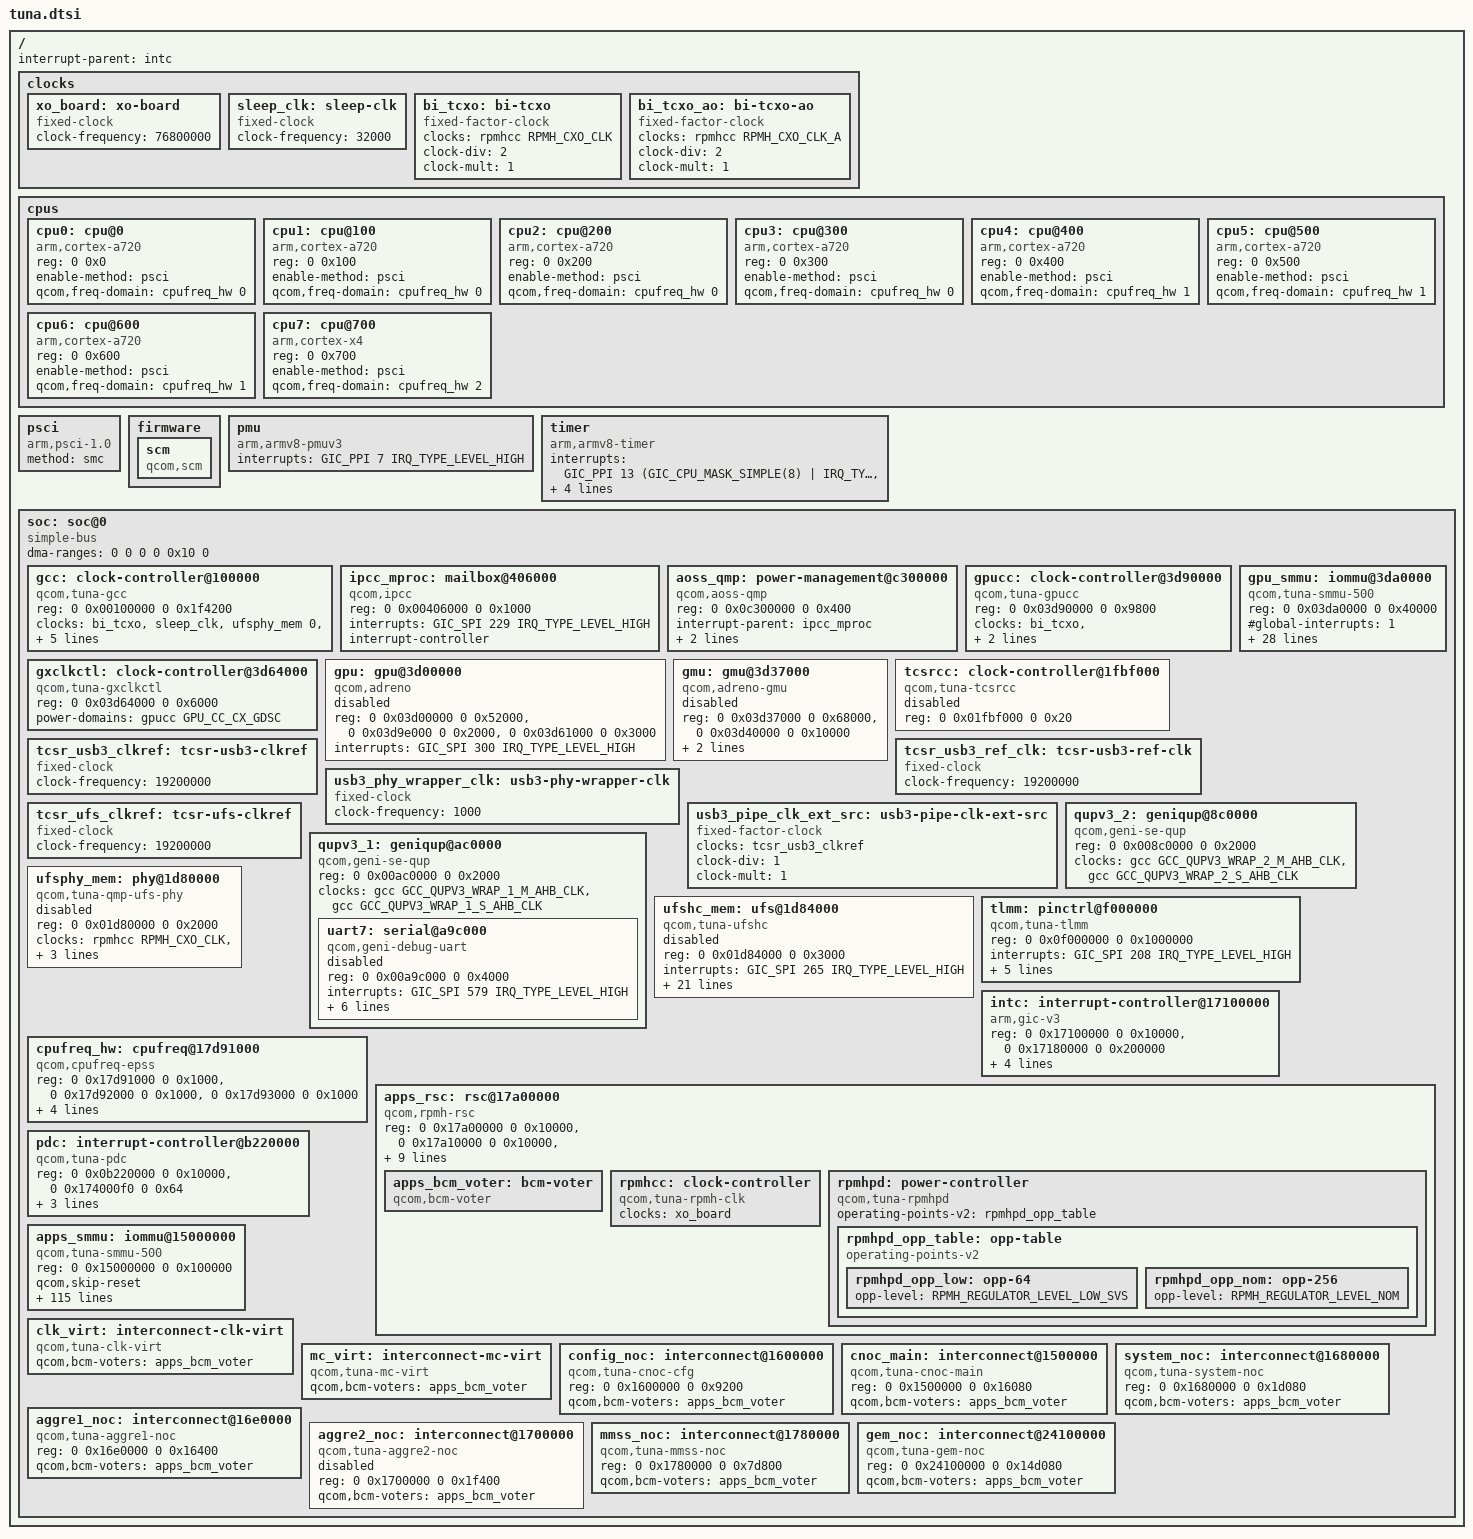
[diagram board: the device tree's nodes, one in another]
// SPDX-License-Identifier: BSD-3-Clause
/* Qualcomm SM8735 (TUNA). Addresses/topology from the captured firmware DT. */
#include <dt-bindings/clock/qcom,gcc-tuna.h>
#include <dt-bindings/clock/qcom,gpucc-tuna.h>
#include <dt-bindings/clock/qcom,dispcc-tuna.h>
#include <dt-bindings/clock/qcom,tcsrcc-sun.h>
#include <dt-bindings/clock/qcom,dsi-phy-28nm.h>
#include <dt-bindings/clock/qcom,rpmh.h>
#include <dt-bindings/gpio/gpio.h>
#include <dt-bindings/interrupt-controller/arm-gic.h>
#include <dt-bindings/interconnect/qcom,tuna.h>
#include <dt-bindings/phy/phy-qcom-qmp.h>
#include <dt-bindings/interconnect/qcom,icc.h>
#include <dt-bindings/power/qcom,rpmhpd.h>
#include <dt-bindings/power/qcom-rpmpd.h>
#include <dt-bindings/soc/qcom,rpmh-rsc.h>

/ {
	#address-cells = <2>;
	#size-cells = <2>;
	interrupt-parent = <&intc>;

	clocks {
		xo_board: xo-board {
			compatible = "fixed-clock";
			clock-frequency = <76800000>;
			#clock-cells = <0>;
		};
		sleep_clk: sleep-clk {
			compatible = "fixed-clock";
			clock-frequency = <32000>;
			#clock-cells = <0>;
		};
		bi_tcxo: bi-tcxo {
			compatible = "fixed-factor-clock";
			clocks = <&rpmhcc RPMH_CXO_CLK>;
			clock-div = <2>;
			clock-mult = <1>;
			#clock-cells = <0>;
		};
		bi_tcxo_ao: bi-tcxo-ao {
			compatible = "fixed-factor-clock";
			clocks = <&rpmhcc RPMH_CXO_CLK_A>;
			clock-div = <2>;
			clock-mult = <1>;
			#clock-cells = <0>;
		};
	};

	cpus {
		#address-cells = <2>;
		#size-cells = <0>;
		cpu0: cpu@0 {
			device_type = "cpu";
			compatible = "arm,cortex-a720";
			reg = <0 0x0>;
			enable-method = "psci";
			#cooling-cells = <2>;
			qcom,freq-domain = <&cpufreq_hw 0>;
		};
		cpu1: cpu@100 {
			device_type = "cpu";
			compatible = "arm,cortex-a720";
			reg = <0 0x100>;
			enable-method = "psci";
			#cooling-cells = <2>;
			qcom,freq-domain = <&cpufreq_hw 0>;
		};
		cpu2: cpu@200 {
			device_type = "cpu";
			compatible = "arm,cortex-a720";
			reg = <0 0x200>;
			enable-method = "psci";
			#cooling-cells = <2>;
			qcom,freq-domain = <&cpufreq_hw 0>;
		};
		cpu3: cpu@300 {
			device_type = "cpu";
			compatible = "arm,cortex-a720";
			reg = <0 0x300>;
			enable-method = "psci";
			#cooling-cells = <2>;
			qcom,freq-domain = <&cpufreq_hw 0>;
		};
		cpu4: cpu@400 {
			device_type = "cpu";
			compatible = "arm,cortex-a720";
			reg = <0 0x400>;
			enable-method = "psci";
			#cooling-cells = <2>;
			qcom,freq-domain = <&cpufreq_hw 1>;
		};
		cpu5: cpu@500 {
			device_type = "cpu";
			compatible = "arm,cortex-a720";
			reg = <0 0x500>;
			enable-method = "psci";
			#cooling-cells = <2>;
			qcom,freq-domain = <&cpufreq_hw 1>;
		};
		cpu6: cpu@600 {
			device_type = "cpu";
			compatible = "arm,cortex-a720";
			reg = <0 0x600>;
			enable-method = "psci";
			#cooling-cells = <2>;
			qcom,freq-domain = <&cpufreq_hw 1>;
		};
		cpu7: cpu@700 {
			device_type = "cpu";
			compatible = "arm,cortex-x4";
			reg = <0 0x700>;
			enable-method = "psci";
			#cooling-cells = <2>;
			qcom,freq-domain = <&cpufreq_hw 2>;
		};
	};

	psci { compatible = "arm,psci-1.0"; method = "smc"; };
	firmware { scm: scm { compatible = "qcom,scm"; }; };
	pmu { compatible = "arm,armv8-pmuv3"; interrupts = <GIC_PPI 7 IRQ_TYPE_LEVEL_HIGH>; };
	timer {
		compatible = "arm,armv8-timer";
		/* Four PPIs and the CPU mask match the captured firmware DT. */
		interrupts = <GIC_PPI 13 (GIC_CPU_MASK_SIMPLE(8) | IRQ_TYPE_LEVEL_LOW)>,
			     <GIC_PPI 14 (GIC_CPU_MASK_SIMPLE(8) | IRQ_TYPE_LEVEL_LOW)>,
			     <GIC_PPI 11 (GIC_CPU_MASK_SIMPLE(8) | IRQ_TYPE_LEVEL_LOW)>,
			     <GIC_PPI 12 (GIC_CPU_MASK_SIMPLE(8) | IRQ_TYPE_LEVEL_LOW)>;
		clock-frequency = <19200000>;
	};

	soc: soc@0 {
		compatible = "simple-bus";
		#address-cells = <2>;
		#size-cells = <2>;
		ranges = <0 0 0 0 0x10 0>;
		dma-ranges = <0 0 0 0 0x10 0>;

		gcc: clock-controller@100000 {
			compatible = "qcom,tuna-gcc";
			reg = <0 0x00100000 0 0x1f4200>;
			clocks = <&bi_tcxo>, <&sleep_clk>,
				 <&ufsphy_mem 0>, <&ufsphy_mem 1>, <&ufsphy_mem 2>,
				 <&usb3_phy_wrapper_clk>;
			clock-names = "bi_tcxo", "sleep_clk", "ufs_phy_rx_symbol_0_clk",
				      "ufs_phy_rx_symbol_1_clk", "ufs_phy_tx_symbol_0_clk",
				      "usb3_phy_wrapper_gcc_usb30_pipe_clk";
			power-domains = <&rpmhpd RPMHPD_CX>, <&rpmhpd RPMHPD_MX>;
			required-opps = <&rpmhpd_opp_nom>, <&rpmhpd_opp_nom>;
			#clock-cells = <1>;
			#reset-cells = <1>;
			#power-domain-cells = <1>;
		};

		/*
		 * The GPU clock controller and the GX clock/power block. Both were
		 * missing from this file while gpucc-tuna.c sat in the tree
		 * unbuilt, which is why the GPU had no way to be clocked no matter
		 * what the board file declared.
		 *
		 * Addresses, window sizes and the clock inputs come from the
		 * board's factory device tree, which names the same blocks
		 * "qcom,tuna-gpucc" and "qcom,tuna-gx_clkctl". The window is
		 * 0x9800 because gpucc-tuna.c's regmap has max_register 0x964c;
		 * a smaller window would truncate it.
		 *
		 * The two GPLL0 inputs are the ones gcc-tuna.c registers. The
		 * driver used to ask for "gpll0_out_main"/"gpll0_out_main_div",
		 * which nothing on this platform provides -- see the note in
		 * gpucc-tuna.c.
		 */
		/*
		 * IPCC and the AOSS QMP that rides on it.
		 *
		 * The GPU needs these. a6xx_gmu_acd_probe() sends the GPU's ACD state to
		 * AOSS with qmp_send(), and refuses to continue when the GPU has ACD
		 * levels but qcom,qmp is absent ("Unable to send ACD state to AOSS",
		 * -EINVAL). This part has ACD -- the vendor's gen8_6_0 entry lists
		 * ADRENO_ACD -- and the vendor sends that state as the very first thing
		 * in gen8_gmu_first_boot, before the CX GDSC, before the clocks and
		 * before the firmware is loaded.
		 *
		 * Both nodes come from the SoC's own vendor device tree, including the
		 * IPCC client/signal numbers; the vendor's GMU node carries
		 * qcom,qmp = <&aoss_qmp>, which is the property the driver reads through
		 * qmp_get().
		 */
		ipcc_mproc: mailbox@406000 {
			compatible = "qcom,ipcc";
			reg = <0 0x00406000 0 0x1000>;
			interrupts = <GIC_SPI 229 IRQ_TYPE_LEVEL_HIGH>;
			interrupt-controller;
			#interrupt-cells = <3>;
			#mbox-cells = <2>;
		};

		aoss_qmp: power-management@c300000 {
			compatible = "qcom,aoss-qmp";
			reg = <0 0x0c300000 0 0x400>;
			interrupt-parent = <&ipcc_mproc>;
			interrupts = <0 0 IRQ_TYPE_EDGE_RISING>;
			mboxes = <&ipcc_mproc 0 0>;
			#power-domain-cells = <1>;
			#clock-cells = <0>;
		};

		gpucc: clock-controller@3d90000 {
			compatible = "qcom,tuna-gpucc";
			reg = <0 0x03d90000 0 0x9800>;
			clocks = <&bi_tcxo>,
				 <&gcc GCC_GPU_GPLL0_CPH_CLK_SRC>,
				 <&gcc GCC_GPU_GPLL0_DIV_CPH_CLK_SRC>;
			clock-names = "bi_tcxo", "gcc_gpu_gpll0_cph_clk_src",
				      "gcc_gpu_gpll0_div_cph_clk_src";
			#clock-cells = <1>;
			#reset-cells = <1>;
			#power-domain-cells = <1>;
		};

		/*
		 * The GX rail. Its GDSC is what the GPU core sits on, and it is
		 * parented to gpucc's power domain, so this node has to follow
		 * gpucc rather than be declared before it.
		 */
		gxclkctl: clock-controller@3d64000 {
			compatible = "qcom,tuna-gxclkctl";
			/*
			 * The block starts at 0x3d64000 and the GX GDSC register is
			 * at offset 0x4024 inside it, which is the 0x3d68024 the
			 * factory device tree names. Declaring the base as 0x3d68024
			 * with a size of 8 -- as this node first did -- gives a
			 * regmap whose offsets are counted from the wrong place, so
			 * the driver would have read and written the wrong register
			 * even once it matched.
			 *
			 * kaanapali.dtsi declares the same block the same way
			 * (0x3d64000, size 0x6000), which is what this follows.
			 */
			reg = <0 0x03d64000 0 0x6000>;

			/*
			 * The GX rail's parents. RPMHPD_GFX and RPMHPD_GMXC are the
			 * RPMh corners and gpucc's CX GDSC is the local one, same
			 * three as kaanapali's node. Without these the rail has no
			 * supply to switch, which matters because this is the domain
			 * the GPU core comes up on.
			 */
			/*
			 * One domain, which is what the SoC's own vendor devicetree
			 * says (oneplus-dt .../devicetree/qcom/tuna.dtsi):
			 *
			 *     gxclkctl: clock-controller@3d68024 {
			 *             compatible = "qcom,tuna-gx_clkctl";
			 *             reg = <0x3d68024 0x8>;
			 *             power-domains = <&gpucc GPU_CC_CX_GDSC>;
			 *             vdd_gx-supply = <&VDD_GFX_MXC_VOTER_LEVEL>;
			 *     };
			 *
			 * This node previously carried three domains copied from
			 * kaanapali.dtsi (RPMHPD_GFX, RPMHPD_GMXC and the CX GDSC).
			 * kaanapali is a different SoC and that was the mistake
			 * AGENTS.md section 6.1 warns about: sibling values are a
			 * reading dictionary, not a source. The vdd_gx supply is a
			 * qcom,stub-regulator in the vendor tree, i.e. a bring-up
			 * placeholder rather than a real rail, so voltage is left to
			 * RPMh here for the same reason.
			 */
			power-domains = <&gpucc GPU_CC_CX_GDSC>;

			#power-domain-cells = <1>;
		};

		/*
		 * The GPU's own SMMU. Address, interrupt list and the clock/power
		 * inputs come from the board's factory device tree, which names
		 * the same block "kgsl-smmu@3da0000" with
		 * compatible = "qcom,qsmmu-v500", "qcom,adreno-smmu".
		 *
		 * The compatible list is reordered for mainline, whose binding
		 * wants the SoC-specific string first: sm8650.dtsi, whose
		 * adreno_smmu sits at this very address with the same first ten
		 * global interrupts (GIC_SPI 673, then 677-687), is the template.
		 * Beyond those ten the two parts differ, so the full 25-interrupt
		 * list here is the vendor's, not sm8650's.
		 *
		 * qcom,use-3-lvl-tables is a vendor property and is deliberately
		 * not carried over: mainline's arm-smmu-qcom sets the table format
		 * from the compatible, and passing a vendor-only property would
		 * have no effect while looking like it did.
		 */
		gpu_smmu: iommu@3da0000 {
			compatible = "qcom,tuna-smmu-500", "qcom,adreno-smmu",
				     "qcom,smmu-500", "arm,mmu-500";
			reg = <0 0x03da0000 0 0x40000>;
			#iommu-cells = <2>;
			#global-interrupts = <1>;
			interrupts = <GIC_SPI 673 IRQ_TYPE_LEVEL_HIGH>,
				     <GIC_SPI 677 IRQ_TYPE_LEVEL_HIGH>,
				     <GIC_SPI 678 IRQ_TYPE_LEVEL_HIGH>,
				     <GIC_SPI 679 IRQ_TYPE_LEVEL_HIGH>,
				     <GIC_SPI 680 IRQ_TYPE_LEVEL_HIGH>,
				     <GIC_SPI 681 IRQ_TYPE_LEVEL_HIGH>,
				     <GIC_SPI 682 IRQ_TYPE_LEVEL_HIGH>,
				     <GIC_SPI 683 IRQ_TYPE_LEVEL_HIGH>,
				     <GIC_SPI 684 IRQ_TYPE_LEVEL_HIGH>,
				     <GIC_SPI 685 IRQ_TYPE_LEVEL_HIGH>,
				     <GIC_SPI 686 IRQ_TYPE_LEVEL_HIGH>,
				     <GIC_SPI 687 IRQ_TYPE_LEVEL_HIGH>,
				     <GIC_SPI 422 IRQ_TYPE_LEVEL_HIGH>,
				     <GIC_SPI 476 IRQ_TYPE_LEVEL_HIGH>,
				     <GIC_SPI 574 IRQ_TYPE_LEVEL_HIGH>,
				     <GIC_SPI 575 IRQ_TYPE_LEVEL_HIGH>,
				     <GIC_SPI 576 IRQ_TYPE_LEVEL_HIGH>,
				     <GIC_SPI 577 IRQ_TYPE_LEVEL_HIGH>,
				     <GIC_SPI 659 IRQ_TYPE_LEVEL_HIGH>,
				     <GIC_SPI 661 IRQ_TYPE_LEVEL_HIGH>,
				     <GIC_SPI 664 IRQ_TYPE_LEVEL_HIGH>,
				     <GIC_SPI 665 IRQ_TYPE_LEVEL_HIGH>,
				     <GIC_SPI 666 IRQ_TYPE_LEVEL_HIGH>,
				     <GIC_SPI 668 IRQ_TYPE_LEVEL_HIGH>,
				     <GIC_SPI 699 IRQ_TYPE_LEVEL_HIGH>;
			clocks = <&gpucc GPU_CC_HLOS1_VOTE_GPU_SMMU_CLK>;
			clock-names = "gpu_cc_hlos1_vote_gpu_smmu";
			power-domains = <&gpucc 1>;
			dma-coherent;
		};

		/*
		 * The GPU and its GMU. Both addresses, the interrupt numbers and the
		 * register windows come from the board's factory device tree, which
		 * names them "kgsl-3d0@3d00000" and "qcom,gmu@3d37000".
		 *
		 * They are siblings, not parent and child: mainline reaches the GMU
		 * through the GPU node's qcom,gmu phandle, which the board file sets,
		 * and both therefore have to be real platform devices.
		 *
		 * The GPU status stays disabled here and is enabled per board, since
		 * which chip id the node advertises is a property of the part fitted.
		 */
		gpu: gpu@3d00000 {
			compatible = "qcom,adreno";
			reg = <0 0x03d00000 0 0x52000>,
			      <0 0x03d9e000 0 0x2000>,
			      <0 0x03d61000 0 0x3000>;
			reg-names = "kgsl_3d0_reg_memory", "cx_mem", "cx_dbgc";
			interrupts = <GIC_SPI 300 IRQ_TYPE_LEVEL_HIGH>;
			interrupt-names = "kgsl_3d0_irq";
			status = "disabled";
		};

		gmu: gmu@3d37000 {
			compatible = "qcom,adreno-gmu";
			reg = <0 0x03d37000 0 0x68000>,
			      <0 0x03d40000 0 0x10000>;
			reg-names = "gmu", "gmu_ao_blk_dec0";
			interrupts = <GIC_SPI 304 IRQ_TYPE_LEVEL_HIGH>,
				     <GIC_SPI 305 IRQ_TYPE_LEVEL_HIGH>;
			interrupt-names = "hfi", "gmu";
			status = "disabled";
		};

		tcsrcc: clock-controller@1fbf000 {
			compatible = "qcom,tuna-tcsrcc";
			reg = <0 0x01fbf000 0 0x20>;
			#clock-cells = <1>;
			/*
			 * The TCSR block is closed to the non-secure kernel -- merely probing its
			 * clock driver stalls the AXI bus -- so the reference gates the bootloader
			 * already opened are modelled as fixed clocks. Enabling it instead leaves
			 * the provider absent, the eUSB2 PHY's devm_clk_get() deferred forever and
			 * the board without USB.
			 */
			status = "disabled";
		};

		/*
		 * The PHY's reference is ref_clk_src, taken from the TCSR syscon and
		 * routed through the pipe_clk_ext_src mux that the vendor driver switches
		 * between bring-up and teardown. TCSR is closed to the non-secure kernel,
		 * so both are fixed clocks. mainline has no generic DT clock mux, so the
		 * mux is a fixed-factor clock sourced from ref_clk_src -- the parent the
		 * vendor driver selects.
		 */
		tcsr_usb3_clkref: tcsr-usb3-clkref {
			compatible = "fixed-clock";
			#clock-cells = <0>;
			clock-frequency = <19200000>;
		};

		tcsr_usb3_ref_clk: tcsr-usb3-ref-clk {
			compatible = "fixed-clock";
			#clock-cells = <0>;
			clock-frequency = <19200000>;
		};

		/*
		 * gcc-tuna.c looks this mux's parents up by fw_name, and GCC probes long
		 * before the QMP PHY: pointing the entry at the PHY leaves parent 0 NULL,
		 * the mux selects nothing and the PIPE chain reports rate 0 with
		 * clk_round_rate() = -EINVAL. With no PIPE clock the link never trains
		 * above High Speed, where the vendor's comes up at SuperSpeed. 1000 Hz is
		 * the placeholder rate the vendor's clock tree reports.
		 */
		usb3_phy_wrapper_clk: usb3-phy-wrapper-clk {
			compatible = "fixed-clock";
			#clock-cells = <0>;
			clock-frequency = <1000>;
		};

		usb3_pipe_clk_ext_src: usb3-pipe-clk-ext-src {
			compatible = "fixed-factor-clock";
			clocks = <&tcsr_usb3_clkref>;
			clock-div = <1>;
			clock-mult = <1>;
			#clock-cells = <0>;
		};

		tcsr_ufs_clkref: tcsr-ufs-clkref {
			compatible = "fixed-clock";
			#clock-cells = <0>;
			clock-frequency = <19200000>;
		};

		/*
		 * The second GENI QUP wrapper. WRAP 2 is where this board's I2C
		 * devices actually are -- see meizu-m2582-i2c.dtsi -- and it was
		 * missing from this file entirely, so its children could not be
		 * declared at all.
		 *
		 * The window, the two AHB clocks and the SE clock indices are each
		 * confirmed twice: by the board's vendor device tree overlay
		 * (qupv3_2 at 0x8c0000, clocks <&gcc 0x6d>, <&gcc 0x6e>, and
		 * <&gcc 0x59..0x5f> for its serial engines) and by qcom,gcc-tuna.h,
		 * where those indices are exactly GCC_QUPV3_WRAP_2_M_AHB_CLK,
		 * GCC_QUPV3_WRAP_2_S_AHB_CLK and GCC_QUPV3_WRAP2_S0..S7_CLK.
		 *
		 * Its serial engines live in meizu-m2582-i2c.dtsi rather than here,
		 * because which of them this board wires up is a board fact.
		 */
		qupv3_2: geniqup@8c0000 {
			compatible = "qcom,geni-se-qup";
			reg = <0 0x008c0000 0 0x2000>;
			clocks = <&gcc GCC_QUPV3_WRAP_2_M_AHB_CLK>, <&gcc GCC_QUPV3_WRAP_2_S_AHB_CLK>;
			clock-names = "m-ahb", "s-ahb";
			#address-cells = <2>;
			#size-cells = <2>;
			ranges;
		};

		qupv3_1: geniqup@ac0000 {
			compatible = "qcom,geni-se-qup";
			reg = <0 0x00ac0000 0 0x2000>;
			clocks = <&gcc GCC_QUPV3_WRAP_1_M_AHB_CLK>, <&gcc GCC_QUPV3_WRAP_1_S_AHB_CLK>;
			clock-names = "m-ahb", "s-ahb";
			#address-cells = <2>;
			#size-cells = <2>;
			ranges;

			uart7: serial@a9c000 {
				compatible = "qcom,geni-debug-uart";
				reg = <0 0x00a9c000 0 0x4000>;
				interrupts = <GIC_SPI 579 IRQ_TYPE_LEVEL_HIGH>;
				clocks = <&gcc GCC_QUPV3_WRAP1_S7_CLK>;
				clock-names = "se";
				interconnects = <&clk_virt MASTER_QUP_CORE_1 QCOM_ICC_TAG_ALWAYS &clk_virt SLAVE_QUP_CORE_1 QCOM_ICC_TAG_ALWAYS>,
						<&gem_noc MASTER_APPSS_PROC QCOM_ICC_TAG_ALWAYS &config_noc SLAVE_QUP_1 QCOM_ICC_TAG_ALWAYS>;
				interconnect-names = "qup-core", "qup-config";
				status = "disabled";
			};
		};

		ufsphy_mem: phy@1d80000 {
			compatible = "qcom,tuna-qmp-ufs-phy";
			reg = <0 0x01d80000 0 0x2000>;
			clocks = <&rpmhcc RPMH_CXO_CLK>, <&gcc GCC_UFS_PHY_PHY_AUX_CLK>, <&tcsr_ufs_clkref>;
			clock-names = "ref", "ref_aux", "qref";
			resets = <&ufshc_mem 0>;
			reset-names = "ufsphy";
			power-domains = <&gcc GCC_UFS_MEM_PHY_GDSC>;
			#clock-cells = <1>;
			#phy-cells = <0>;
			status = "disabled";
		};

		ufshc_mem: ufs@1d84000 {
			compatible = "qcom,tuna-ufshc", "qcom,ufshc", "jedec,ufs-2.0";
			reg = <0 0x01d84000 0 0x3000>;
			interrupts = <GIC_SPI 265 IRQ_TYPE_LEVEL_HIGH>;
			clocks = <&gcc GCC_UFS_PHY_AXI_CLK>, <&gcc GCC_AGGRE_UFS_PHY_AXI_CLK>,
				 <&gcc GCC_UFS_PHY_AHB_CLK>, <&gcc GCC_UFS_PHY_UNIPRO_CORE_CLK>,
				 <&rpmhcc RPMH_LN_BB_CLK3>, <&gcc GCC_UFS_PHY_TX_SYMBOL_0_CLK>,
				 <&gcc GCC_UFS_PHY_RX_SYMBOL_0_CLK>, <&gcc GCC_UFS_PHY_RX_SYMBOL_1_CLK>;
			clock-names = "core_clk", "bus_aggr_clk", "iface_clk", "core_clk_unipro",
				      "ref_clk", "tx_lane0_sync_clk", "rx_lane0_sync_clk", "rx_lane1_sync_clk";
			/*
			 * A non-zero min/max range makes the UFS core register a devfreq device,
			 * and ufs_devfreq_scale() then walks of_parse_clkspec() every 60 ms -- a
			 * path that oopses on this board in __pi_strcmp about two seconds into
			 * boot. Collapsing each range to one value keeps the property present
			 * while making scaling impossible. Pin to the top of the range: at 100 MHz
			 * the link does not work at all.
			 */
			freq-table-hz = <403000000 403000000>, <0 0>, <0 0>, <403000000 403000000>,
					<0 0>, <0 0>, <0 0>, <0 0>;
			interconnects = <&aggre1_noc MASTER_UFS_MEM QCOM_ICC_TAG_ALWAYS &mc_virt SLAVE_EBI1 QCOM_ICC_TAG_ALWAYS>,
					<&gem_noc MASTER_APPSS_PROC QCOM_ICC_TAG_ALWAYS &config_noc SLAVE_UFS_MEM_CFG QCOM_ICC_TAG_ALWAYS>;
			interconnect-names = "ufs-ddr", "cpu-ufs";
			power-domains = <&gcc GCC_UFS_PHY_GDSC>;
			dma-coherent;
			lanes-per-direction = <2>;
			phys = <&ufsphy_mem>;
			phy-names = "ufsphy";
			resets = <&gcc GCC_UFS_PHY_BCR>;
			reset-names = "rst";
			reset-gpios = <&tlmm 191 GPIO_ACTIVE_LOW>;
			#reset-cells = <1>;
			status = "disabled";
		};

		tlmm: pinctrl@f000000 {
			compatible = "qcom,tuna-tlmm";
			reg = <0 0x0f000000 0 0x1000000>;
			interrupts = <GIC_SPI 208 IRQ_TYPE_LEVEL_HIGH>;
			gpio-controller;
			#gpio-cells = <2>;
			interrupt-controller;
			#interrupt-cells = <2>;
			#address-cells = <0>;
			gpio-ranges = <&tlmm 0 0 192>;
			gpio-reserved-ranges = <4 4>, <54 1>, <82 2>;
			wakeup-parent = <&pdc>;
		};

		intc: interrupt-controller@17100000 {
			compatible = "arm,gic-v3";
			reg = <0 0x17100000 0 0x10000>, <0 0x17180000 0 0x200000>;
			interrupts = <GIC_PPI 9 IRQ_TYPE_LEVEL_HIGH>;
			interrupt-controller;
			#interrupt-cells = <3>;
			#address-cells = <2>;
			#size-cells = <2>;
			ranges;
			#redistributor-regions = <1>;
			redistributor-stride = <0 0x40000>;
		};

		/*
		 * EPSS runs CPU DVFS in hardware. An RPMh vote only lands if it agrees
		 * with what the firmware already programmed, so frequency and voltage
		 * scaling happen here rather than in the OS. Addresses, clocks and
		 * interrupts are from the factory device tree; the layout matches
		 * sm8250's EPSS, only the base differs.
		 */
		cpufreq_hw: cpufreq@17d91000 {
			compatible = "qcom,cpufreq-epss";
			reg = <0 0x17d91000 0 0x1000>,
			      <0 0x17d92000 0 0x1000>,
			      <0 0x17d93000 0 0x1000>;
			reg-names = "freq-domain0", "freq-domain1", "freq-domain2";

			/*
			 * "xo" must be the divided 19.2 MHz clock, not RPMH_CXO_CLK
			 * itself. The driver turns an LUT entry into a frequency as
			 * xo_rate * lval / 1000, so feeding it the undivided 38.4 MHz
			 * doubles every frequency it reports -- which is exactly what
			 * happened: the hardware LUT tops out at 2016/2803/3206 MHz
			 * for the three domains, matching the A720 silver, A720 gold
			 * and X4 parts, but the driver announced 4032/5414/5913 MHz.
			 * bi_tcxo below is the fixed divide-by-2 of RPMH_CXO_CLK;
			 * sm8650 and sm8750 name the same thing bi_tcxo_div2.
			 */
			clocks = <&bi_tcxo>, <&gcc GCC_GPLL0>;
			clock-names = "xo", "alternate";

			interrupts = <GIC_SPI 30 IRQ_TYPE_LEVEL_HIGH>,
				     <GIC_SPI 31 IRQ_TYPE_LEVEL_HIGH>,
				     <GIC_SPI 19 IRQ_TYPE_LEVEL_HIGH>;
			interrupt-names = "dcvsh-irq-0", "dcvsh-irq-1", "dcvsh-irq-2";

			#freq-domain-cells = <1>;
		};

		apps_rsc: rsc@17a00000 {
			compatible = "qcom,rpmh-rsc";
			reg = <0 0x17a00000 0 0x10000>, <0 0x17a10000 0 0x10000>, <0 0x17a20000 0 0x10000>;
			reg-names = "drv-0", "drv-1", "drv-2";
			interrupts = <GIC_SPI 3 IRQ_TYPE_LEVEL_HIGH>, <GIC_SPI 4 IRQ_TYPE_LEVEL_HIGH>, <GIC_SPI 5 IRQ_TYPE_LEVEL_HIGH>;
			qcom,drv-id = <2>;
			qcom,tcs-offset = <0xd00>;
			qcom,tcs-config = <ACTIVE_TCS 3>, <SLEEP_TCS 2>, <WAKE_TCS 2>, <CONTROL_TCS 0>;
			label = "apps_rsc";
			apps_bcm_voter: bcm-voter { compatible = "qcom,bcm-voter"; };
			rpmhcc: clock-controller {
				compatible = "qcom,tuna-rpmh-clk";
				clocks = <&xo_board>;
				clock-names = "xo";
				#clock-cells = <1>;
			};
			rpmhpd: power-controller {
				compatible = "qcom,tuna-rpmhpd";
				#power-domain-cells = <1>;
				operating-points-v2 = <&rpmhpd_opp_table>;
				rpmhpd_opp_table: opp-table {
					compatible = "operating-points-v2";
					rpmhpd_opp_low: opp-64 { opp-level = <RPMH_REGULATOR_LEVEL_LOW_SVS>; };
					rpmhpd_opp_nom: opp-256 { opp-level = <RPMH_REGULATOR_LEVEL_NOM>; };
				};
			};
		};

		pdc: interrupt-controller@b220000 {
			compatible = "qcom,tuna-pdc", "qcom,pdc";
			reg = <0 0x0b220000 0 0x10000>, <0 0x174000f0 0 0x64>;
			#interrupt-cells = <2>;
			#address-cells = <0>;
			interrupt-controller;
			qcom,pdc-ranges = <0 480 8 8 719 1 9 718 1 10 230 1 11 724 1 12 716 1 13 727 1 14 720 1 15 726 1 16 721 1 17 262 1 18 70 1 19 723 1 20 234 1 22 725 1 23 231 1 24 504 14 40 520 6 51 531 4 58 538 2 61 541 4 67 547 27 94 609 31 125 63 1 126 366 2 128 374 1 129 378 1 130 428 1 131 434 2 133 437 1 134 452 2 136 458 2 138 464 11 149 671 1 150 688 1 151 714 2 153 722 1 154 255 1 155 269 2 157 276 1 158 287 1 159 306 4>;
		};

		apps_smmu: iommu@15000000 {
			compatible = "qcom,tuna-smmu-500", "qcom,smmu-500", "arm,mmu-500";
			reg = <0 0x15000000 0 0x100000>;
			/*
			 * Removing this property takes the board down: black screen, no USB
			 * enumeration, no console. The bootloader leaves this SMMU translating
			 * for UFS and USB, and re-initialising every SMR and context bank from
			 * the non-secure kernel breaks them. Verified as an isolated change.
			 */
			qcom,skip-reset;
			#iommu-cells = <2>;
			#global-interrupts = <1>;
			dma-coherent;
			interrupts = <GIC_SPI 65 IRQ_TYPE_LEVEL_HIGH>,
				     <GIC_SPI 97 IRQ_TYPE_LEVEL_HIGH>,
				     <GIC_SPI 98 IRQ_TYPE_LEVEL_HIGH>,
				     <GIC_SPI 99 IRQ_TYPE_LEVEL_HIGH>,
				     <GIC_SPI 100 IRQ_TYPE_LEVEL_HIGH>,
				     <GIC_SPI 101 IRQ_TYPE_LEVEL_HIGH>,
				     <GIC_SPI 102 IRQ_TYPE_LEVEL_HIGH>,
				     <GIC_SPI 103 IRQ_TYPE_LEVEL_HIGH>,
				     <GIC_SPI 104 IRQ_TYPE_LEVEL_HIGH>,
				     <GIC_SPI 105 IRQ_TYPE_LEVEL_HIGH>,
				     <GIC_SPI 106 IRQ_TYPE_LEVEL_HIGH>,
				     <GIC_SPI 107 IRQ_TYPE_LEVEL_HIGH>,
				     <GIC_SPI 108 IRQ_TYPE_LEVEL_HIGH>,
				     <GIC_SPI 109 IRQ_TYPE_LEVEL_HIGH>,
				     <GIC_SPI 110 IRQ_TYPE_LEVEL_HIGH>,
				     <GIC_SPI 111 IRQ_TYPE_LEVEL_HIGH>,
				     <GIC_SPI 112 IRQ_TYPE_LEVEL_HIGH>,
				     <GIC_SPI 113 IRQ_TYPE_LEVEL_HIGH>,
				     <GIC_SPI 114 IRQ_TYPE_LEVEL_HIGH>,
				     <GIC_SPI 115 IRQ_TYPE_LEVEL_HIGH>,
				     <GIC_SPI 116 IRQ_TYPE_LEVEL_HIGH>,
				     <GIC_SPI 117 IRQ_TYPE_LEVEL_HIGH>,
				     <GIC_SPI 118 IRQ_TYPE_LEVEL_HIGH>,
				     <GIC_SPI 181 IRQ_TYPE_LEVEL_HIGH>,
				     <GIC_SPI 182 IRQ_TYPE_LEVEL_HIGH>,
				     <GIC_SPI 183 IRQ_TYPE_LEVEL_HIGH>,
				     <GIC_SPI 184 IRQ_TYPE_LEVEL_HIGH>,
				     <GIC_SPI 185 IRQ_TYPE_LEVEL_HIGH>,
				     <GIC_SPI 186 IRQ_TYPE_LEVEL_HIGH>,
				     <GIC_SPI 187 IRQ_TYPE_LEVEL_HIGH>,
				     <GIC_SPI 188 IRQ_TYPE_LEVEL_HIGH>,
				     <GIC_SPI 189 IRQ_TYPE_LEVEL_HIGH>,
				     <GIC_SPI 190 IRQ_TYPE_LEVEL_HIGH>,
				     <GIC_SPI 191 IRQ_TYPE_LEVEL_HIGH>,
				     <GIC_SPI 192 IRQ_TYPE_LEVEL_HIGH>,
				     <GIC_SPI 315 IRQ_TYPE_LEVEL_HIGH>,
				     <GIC_SPI 316 IRQ_TYPE_LEVEL_HIGH>,
				     <GIC_SPI 317 IRQ_TYPE_LEVEL_HIGH>,
				     <GIC_SPI 318 IRQ_TYPE_LEVEL_HIGH>,
				     <GIC_SPI 319 IRQ_TYPE_LEVEL_HIGH>,
				     <GIC_SPI 320 IRQ_TYPE_LEVEL_HIGH>,
				     <GIC_SPI 321 IRQ_TYPE_LEVEL_HIGH>,
				     <GIC_SPI 322 IRQ_TYPE_LEVEL_HIGH>,
				     <GIC_SPI 323 IRQ_TYPE_LEVEL_HIGH>,
				     <GIC_SPI 324 IRQ_TYPE_LEVEL_HIGH>,
				     <GIC_SPI 325 IRQ_TYPE_LEVEL_HIGH>,
				     <GIC_SPI 326 IRQ_TYPE_LEVEL_HIGH>,
				     <GIC_SPI 327 IRQ_TYPE_LEVEL_HIGH>,
				     <GIC_SPI 328 IRQ_TYPE_LEVEL_HIGH>,
				     <GIC_SPI 329 IRQ_TYPE_LEVEL_HIGH>,
				     <GIC_SPI 330 IRQ_TYPE_LEVEL_HIGH>,
				     <GIC_SPI 331 IRQ_TYPE_LEVEL_HIGH>,
				     <GIC_SPI 332 IRQ_TYPE_LEVEL_HIGH>,
				     <GIC_SPI 333 IRQ_TYPE_LEVEL_HIGH>,
				     <GIC_SPI 334 IRQ_TYPE_LEVEL_HIGH>,
				     <GIC_SPI 335 IRQ_TYPE_LEVEL_HIGH>,
				     <GIC_SPI 336 IRQ_TYPE_LEVEL_HIGH>,
				     <GIC_SPI 337 IRQ_TYPE_LEVEL_HIGH>,
				     <GIC_SPI 338 IRQ_TYPE_LEVEL_HIGH>,
				     <GIC_SPI 339 IRQ_TYPE_LEVEL_HIGH>,
				     <GIC_SPI 340 IRQ_TYPE_LEVEL_HIGH>,
				     <GIC_SPI 341 IRQ_TYPE_LEVEL_HIGH>,
				     <GIC_SPI 342 IRQ_TYPE_LEVEL_HIGH>,
				     <GIC_SPI 343 IRQ_TYPE_LEVEL_HIGH>,
				     <GIC_SPI 344 IRQ_TYPE_LEVEL_HIGH>,
				     <GIC_SPI 345 IRQ_TYPE_LEVEL_HIGH>,
				     <GIC_SPI 395 IRQ_TYPE_LEVEL_HIGH>,
				     <GIC_SPI 396 IRQ_TYPE_LEVEL_HIGH>,
				     <GIC_SPI 397 IRQ_TYPE_LEVEL_HIGH>,
				     <GIC_SPI 398 IRQ_TYPE_LEVEL_HIGH>,
				     <GIC_SPI 399 IRQ_TYPE_LEVEL_HIGH>,
				     <GIC_SPI 400 IRQ_TYPE_LEVEL_HIGH>,
				     <GIC_SPI 401 IRQ_TYPE_LEVEL_HIGH>,
				     <GIC_SPI 402 IRQ_TYPE_LEVEL_HIGH>,
				     <GIC_SPI 403 IRQ_TYPE_LEVEL_HIGH>,
				     <GIC_SPI 404 IRQ_TYPE_LEVEL_HIGH>,
				     <GIC_SPI 405 IRQ_TYPE_LEVEL_HIGH>,
				     <GIC_SPI 406 IRQ_TYPE_LEVEL_HIGH>,
				     <GIC_SPI 407 IRQ_TYPE_LEVEL_HIGH>,
				     <GIC_SPI 408 IRQ_TYPE_LEVEL_HIGH>,
				     <GIC_SPI 409 IRQ_TYPE_LEVEL_HIGH>,
				     <GIC_SPI 418 IRQ_TYPE_LEVEL_HIGH>,
				     <GIC_SPI 419 IRQ_TYPE_LEVEL_HIGH>,
				     <GIC_SPI 412 IRQ_TYPE_LEVEL_HIGH>,
				     <GIC_SPI 421 IRQ_TYPE_LEVEL_HIGH>,
				     <GIC_SPI 707 IRQ_TYPE_LEVEL_HIGH>,
				     <GIC_SPI 423 IRQ_TYPE_LEVEL_HIGH>,
				     <GIC_SPI 424 IRQ_TYPE_LEVEL_HIGH>,
				     <GIC_SPI 425 IRQ_TYPE_LEVEL_HIGH>,
				     <GIC_SPI 690 IRQ_TYPE_LEVEL_HIGH>,
				     <GIC_SPI 691 IRQ_TYPE_LEVEL_HIGH>,
				     <GIC_SPI 692 IRQ_TYPE_LEVEL_HIGH>,
				     <GIC_SPI 693 IRQ_TYPE_LEVEL_HIGH>,
				     <GIC_SPI 694 IRQ_TYPE_LEVEL_HIGH>,
				     <GIC_SPI 695 IRQ_TYPE_LEVEL_HIGH>,
				     <GIC_SPI 696 IRQ_TYPE_LEVEL_HIGH>,
				     <GIC_SPI 697 IRQ_TYPE_LEVEL_HIGH>,
				     <GIC_SPI 410 IRQ_TYPE_LEVEL_HIGH>,
				     <GIC_SPI 488 IRQ_TYPE_LEVEL_HIGH>,
				     <GIC_SPI 489 IRQ_TYPE_LEVEL_HIGH>,
				     <GIC_SPI 490 IRQ_TYPE_LEVEL_HIGH>,
				     <GIC_SPI 491 IRQ_TYPE_LEVEL_HIGH>,
				     <GIC_SPI 492 IRQ_TYPE_LEVEL_HIGH>,
				     <GIC_SPI 493 IRQ_TYPE_LEVEL_HIGH>,
				     <GIC_SPI 494 IRQ_TYPE_LEVEL_HIGH>,
				     <GIC_SPI 495 IRQ_TYPE_LEVEL_HIGH>,
				     <GIC_SPI 496 IRQ_TYPE_LEVEL_HIGH>,
				     <GIC_SPI 497 IRQ_TYPE_LEVEL_HIGH>,
				     <GIC_SPI 498 IRQ_TYPE_LEVEL_HIGH>,
				     <GIC_SPI 499 IRQ_TYPE_LEVEL_HIGH>,
				     <GIC_SPI 500 IRQ_TYPE_LEVEL_HIGH>,
				     <GIC_SPI 501 IRQ_TYPE_LEVEL_HIGH>,
				     <GIC_SPI 502 IRQ_TYPE_LEVEL_HIGH>;
		};

		clk_virt: interconnect-clk-virt {
			compatible = "qcom,tuna-clk-virt";
			#interconnect-cells = <2>;
			qcom,bcm-voters = <&apps_bcm_voter>;
		};

		mc_virt: interconnect-mc-virt {
			compatible = "qcom,tuna-mc-virt";
			#interconnect-cells = <2>;
			qcom,bcm-voters = <&apps_bcm_voter>;
		};

		config_noc: interconnect@1600000 {
			compatible = "qcom,tuna-cnoc-cfg";
			reg = <0 0x1600000 0 0x9200>;
			#interconnect-cells = <2>;
			qcom,bcm-voters = <&apps_bcm_voter>;
		};

		cnoc_main: interconnect@1500000 {
			compatible = "qcom,tuna-cnoc-main";
			reg = <0 0x1500000 0 0x16080>;
			#interconnect-cells = <2>;
			qcom,bcm-voters = <&apps_bcm_voter>;
		};

		system_noc: interconnect@1680000 {
			compatible = "qcom,tuna-system-noc";
			reg = <0 0x1680000 0 0x1d080>;
			#interconnect-cells = <2>;
			qcom,bcm-voters = <&apps_bcm_voter>;
		};

		aggre1_noc: interconnect@16e0000 {
			compatible = "qcom,tuna-aggre1-noc";
			reg = <0 0x16e0000 0 0x16400>;
			#interconnect-cells = <2>;
			qcom,bcm-voters = <&apps_bcm_voter>;
		};

		/*
		 * AGGRE2 sits in a power-collapsed domain. Touching its registers
		 * while that domain is down stalls the AXI bus, and nothing in
		 * this bring-up DT consumes it yet, so it stays off.
		 */
		aggre2_noc: interconnect@1700000 {
			compatible = "qcom,tuna-aggre2-noc";
			reg = <0 0x1700000 0 0x1f400>;
			#interconnect-cells = <2>;
			qcom,bcm-voters = <&apps_bcm_voter>;
			status = "disabled";
		};

		/*
		 * The display path runs over this interconnect. While it is disabled the
		 * interconnect core cannot resolve MASTER_MDP, so msm-mdss fails with
		 * "error finding src node" and DPU, DSI, PHY and panel are never created
		 * -- which is what left /dev/dri empty. It is safe to enable: the provider
		 * is in MMCX, which is already up, and sm8650.dtsi declares no
		 * power-domains for the same NoC either.
		 */
		mmss_noc: interconnect@1780000 {
			compatible = "qcom,tuna-mmss-noc";
			reg = <0 0x1780000 0 0x7d800>;
			#interconnect-cells = <2>;
			qcom,bcm-voters = <&apps_bcm_voter>;
		};

		gem_noc: interconnect@24100000 {
			compatible = "qcom,tuna-gem-noc";
			reg = <0 0x24100000 0 0x14d080>;
			#interconnect-cells = <2>;
			qcom,bcm-voters = <&apps_bcm_voter>;
		};
	};
};
